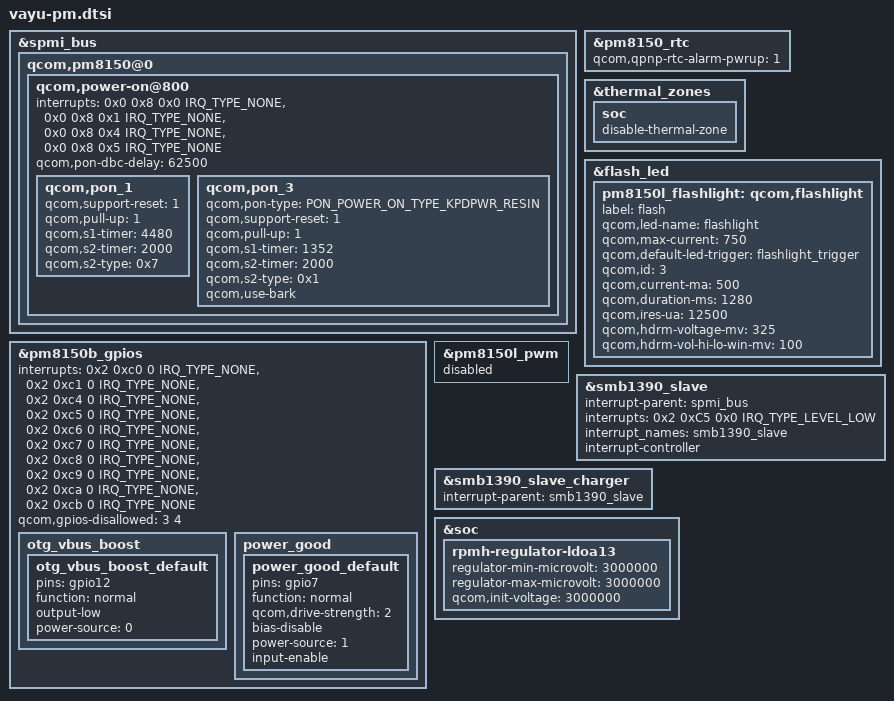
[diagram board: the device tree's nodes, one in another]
/* Copyright (c) 2021, The Linux Foundation. All rights reserved.
*  Copyright (c) 2021, Jebaitedneko <Jebaitedneko@gmail.com>.
*
* This program is free software; you can redistribute it and/or modify
* it under the terms of the GNU General Public License version 2 and
* only version 2 as published by the Free Software Foundation.
*
* This program is distributed in the hope that it will be useful,
* but WITHOUT ANY WARRANTY; without even the implied warranty of
* MERCHANTABILITY or FITNESS FOR A PARTICULAR PURPOSE.  See the
* GNU General Public License for more details.
*/

/* pm8150 */

#include <dt-bindings/input/qcom,qpnp-power-on.h>

&spmi_bus {

	qcom,pm8150@0 {

		qcom,power-on@800 {

			interrupts = <0x0 0x8 0x0 IRQ_TYPE_NONE>,
				   <0x0 0x8 0x1 IRQ_TYPE_NONE>,
				   <0x0 0x8 0x4 IRQ_TYPE_NONE>,
				   <0x0 0x8 0x5 IRQ_TYPE_NONE>;

			interrupt-names = "kpdpwr", "resin",
					"resin-bark", "kpdpwr-resin-bark";

			qcom,pon-dbc-delay = <62500>;

			qcom,pon_1 {

				qcom,support-reset = <1>;
				qcom,pull-up = <1>;
				qcom,s1-timer = <4480>;
				qcom,s2-timer = <2000>;
				qcom,s2-type = <0x7>;
			};

			qcom,pon_3 {

				qcom,pon-type = <PON_POWER_ON_TYPE_KPDPWR_RESIN>;
				qcom,support-reset = <1>;
				qcom,pull-up = <1>;
				qcom,s1-timer = <1352>;
				qcom,s2-timer = <2000>;
				qcom,s2-type = <0x1>;
				qcom,use-bark;
			};
		};
	};
};

&pm8150_rtc {

	qcom,qpnp-rtc-alarm-pwrup = <1>;
};

/* pm8150b */

&pm8150b_gpios {

	interrupts = <0x2 0xc0 0 IRQ_TYPE_NONE>,
			<0x2 0xc1 0 IRQ_TYPE_NONE>,
			<0x2 0xc4 0 IRQ_TYPE_NONE>,
			<0x2 0xc5 0 IRQ_TYPE_NONE>,
			<0x2 0xc6 0 IRQ_TYPE_NONE>,
			<0x2 0xc7 0 IRQ_TYPE_NONE>,
			<0x2 0xc8 0 IRQ_TYPE_NONE>,
			<0x2 0xc9 0 IRQ_TYPE_NONE>,
			<0x2 0xca 0 IRQ_TYPE_NONE>,
			<0x2 0xcb 0 IRQ_TYPE_NONE>;

	interrupt-names = "pm8150b_gpio1", "pm8150b_gpio2",
			"pm8150b_gpio5", "pm8150b_gpio6",
			"pm8150b_gpio7", "pm8150b_gpio8",
			"pm8150b_gpio9", "pm8150b_gpio10",
			"pm8150b_gpio11", "pm8150b_gpio12";

	qcom,gpios-disallowed = <3 4>;
};

&thermal_zones {

	soc {

		disable-thermal-zone;
	};
};

/* pm8150l */

&flash_led {

	pm8150l_flashlight: qcom,flashlight {

		label = "flash";
		qcom,led-name = "flashlight";
		qcom,max-current = <750>;
		qcom,default-led-trigger = "flashlight_trigger";
		qcom,id = <3>;
		qcom,current-ma = <500>;
		qcom,duration-ms = <1280>;
		qcom,ires-ua = <12500>;
		qcom,hdrm-voltage-mv = <325>;
		qcom,hdrm-vol-hi-lo-win-mv = <100>;
	};
};

&pm8150l_pwm {

	status="disabled";
};

/* sm8150-pmic-overlay */

&pm8150b_gpios {

	otg_vbus_boost {

		otg_vbus_boost_default: otg_vbus_boost_default {

			pins = "gpio12";
			function = "normal";
			output-low;
			power-source = <0>;
		};
	};

	power_good {

		/*Get the DC Power Good signal*/
		power_good_default: power_good_default {

			pins = "gpio7";
			function = "normal";
			qcom,drive-strength = <2>; /* 2 MA */
			bias-disable;         /* NO pull */
			power-source = <1>;
			input-enable;
		};
	};
};

/* smb1390 */

&smb1390_slave {

	interrupt-parent = <&spmi_bus>;
	interrupts = <0x2 0xC5 0x0 IRQ_TYPE_LEVEL_LOW>;
	interrupt_names = "smb1390_slave";
	interrupt-controller;
	#interrupt-cells = <3>;
};

&smb1390_slave_charger {

	interrupt-parent = <&smb1390_slave>;
};

/* sm8150-regulator */

&soc {

	rpmh-regulator-ldoa13 {

		regulator-min-microvolt = <3000000>;
		regulator-max-microvolt = <3000000>;
		qcom,init-voltage = <3000000>;
	};
};
